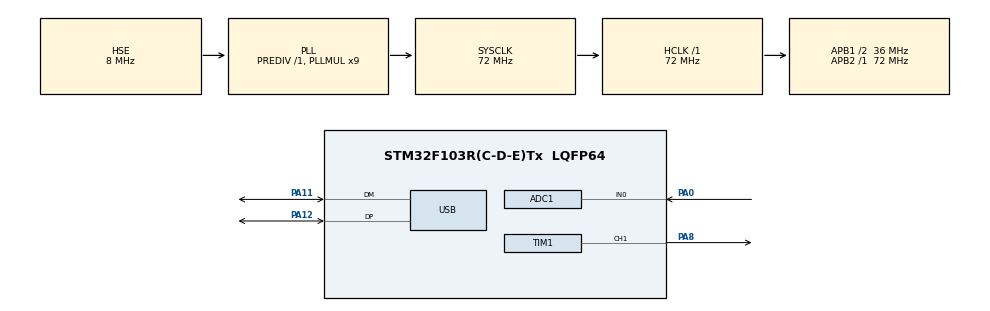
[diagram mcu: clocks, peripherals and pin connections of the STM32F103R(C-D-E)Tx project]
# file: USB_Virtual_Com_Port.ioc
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ADC1.Channel-0\#ChannelRegularConversion=ADC_CHANNEL_0
ADC1.ExternalTrigConv=ADC_EXTERNALTRIGCONV_T3_TRGO
ADC1.InjNumberOfConversion=0
ADC1.NbrOfConversion=1
ADC1.NbrOfConversionFlag=1
ADC1.Rank-0\#ChannelRegularConversion=1
ADC1.SamplingTime-0\#ChannelRegularConversion=ADC_SAMPLETIME_1CYCLE_5
ADC1.master=1
Dma.ADC1.0.Direction=DMA_PERIPH_TO_MEMORY
Dma.ADC1.0.Instance=DMA1_Channel1
Dma.ADC1.0.MemDataAlignment=DMA_MDATAALIGN_HALFWORD
Dma.ADC1.0.MemInc=DMA_MINC_ENABLE
Dma.ADC1.0.Mode=DMA_CIRCULAR
Dma.ADC1.0.PeriphDataAlignment=DMA_PDATAALIGN_HALFWORD
Dma.ADC1.0.PeriphInc=DMA_PINC_DISABLE
Dma.ADC1.0.Priority=DMA_PRIORITY_HIGH
Dma.Request0=ADC1
Mcu.Family=STM32F1
Mcu.Name=STM32F103R(C-D-E)Tx
Mcu.Package=LQFP64
NVIC.DMA1_Channel1_IRQn=true\:0\:0\:false\:false\:true\:false\:true
NVIC.PriorityGroup=NVIC_PRIORITYGROUP_4
NVIC.USB_LP_CAN1_RX0_IRQn=true\:0\:0\:false\:false\:true\:false\:true
PA0-WKUP.Signal=ADCx_IN0
PA11.Mode=Device
PA11.Signal=USB_DM
PA12.Mode=Device
PA12.Signal=USB_DP
PA13.Mode=Serial_Wire
PA13.Signal=SYS_JTMS-SWDIO
PA14.Mode=Serial_Wire
PA14.Signal=SYS_JTCK-SWCLK
PA8.Signal=S_TIM1_CH1
PD0-OSC_IN.Mode=HSE-External-Oscillator
PD0-OSC_IN.Signal=RCC_OSC_IN
PD1-OSC_OUT.Mode=HSE-External-Oscillator
PD1-OSC_OUT.Signal=RCC_OSC_OUT
ProjectManager.HeapSize=0x200
ProjectManager.StackSize=0x400
ProjectManager.TargetToolchain=MDK-ARM V5
RCC.ADCPresc=RCC_ADCPCLK2_DIV6
RCC.AHBFreq_Value=72000000
RCC.APB1CLKDivider=RCC_HCLK_DIV2
RCC.APB1Freq_Value=36000000
RCC.APB1TimFreq_Value=72000000
RCC.APB2Freq_Value=72000000
RCC.APB2TimFreq_Value=72000000
RCC.HCLKFreq_Value=72000000
RCC.PLLMUL=RCC_PLL_MUL9
RCC.PLLSourceVirtual=RCC_PLLSOURCE_HSE
RCC.SYSCLKFreq_VALUE=72000000
RCC.SYSCLKSource=RCC_SYSCLKSOURCE_PLLCLK
RCC.USBFreq_Value=48000000
RCC.USBPrescaler=RCC_USBCLKSOURCE_PLL_DIV1_5
SH.ADCx_IN0.0=ADC1_IN0,IN0
SH.S_TIM1_CH1.0=TIM1_CH1,PWM Generation1 CH1
TIM1.AutomaticOutput=TIM_AUTOMATICOUTPUT_ENABLE
TIM1.Channel-PWM\ Generation1\ CH1=TIM_CHANNEL_1
TIM1.OCPolarity_1=TIM_OCPOLARITY_LOW
TIM1.Period=5000
TIM1.Prescaler=72
TIM1.Pulse-PWM\ Generation1\ CH1=2500
TIM3.Period=1000
TIM3.Prescaler=72
TIM3.TIM_MasterOutputTrigger=TIM_TRGO_UPDATE
USB_DEVICE.APP_RX_DATA_SIZE=50
USB_DEVICE.APP_TX_DATA_SIZE=50
USB_DEVICE.CLASS_NAME_FS=CDC
USB_DEVICE.VirtualMode=Cdc
USB_DEVICE.VirtualModeFS=Cdc_FS
VP_TIM3_VS_ClockSourceINT.Mode=Internal
VP_USB_DEVICE_VS_USB_DEVICE_CDC_FS.Mode=CDC_FS
board=custom

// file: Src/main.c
/* USER CODE BEGIN Header */
/**
  ******************************************************************************
  * @file           : main.c
  * @brief          : Main program body
  ******************************************************************************
  * @attention
  *
  * <h2><center>&copy; Copyright (c) 2020 STMicroelectronics.
  * All rights reserved.</center></h2>
  *
  * This software component is licensed by ST under Ultimate Liberty license
  * SLA0044, the "License"; You may not use this file except in compliance with
  * the License. You may obtain a copy of the License at:
  *                             www.st.com/SLA0044
  *
  ******************************************************************************
  */
/* USER CODE END Header */

#include "main.h"
#include "usb_device.h"

/* USER CODE BEGIN Includes */
uint8_t CDC_Transmit_FS(uint8_t* Buf, uint16_t Len);
/* USER CODE END Includes */

/* USER CODE BEGIN PD */
#define ADC_CALC	3.3/4096
/* USER CODE END PD */

ADC_HandleTypeDef hadc1;
DMA_HandleTypeDef hdma_adc1;

TIM_HandleTypeDef htim1;
TIM_HandleTypeDef htim3;

/* USER CODE BEGIN PV */
uint32_t ADCValue;
char string[]="3.30 Volt \r\n";
/* USER CODE END PV */

void SystemClock_Config(void);
static void MX_GPIO_Init(void);
static void MX_DMA_Init(void);
static void MX_ADC1_Init(void);
static void MX_TIM3_Init(void);
static void MX_TIM1_Init(void);

/* USER CODE BEGIN 0 */
#define APP_RX_DATA_SIZE  50
extern uint8_t UserRxBufferFS[APP_RX_DATA_SIZE];;
/* USER CODE END 0 */

int main(void)
{

  /* MCU Configuration--------------------------------------------------------*/

  /* Reset of all peripherals, Initializes the Flash interface and the Systick. */
  HAL_Init();

  /* Configure the system clock */
  SystemClock_Config();

  /* Initialize all configured peripherals */
  MX_GPIO_Init();
  MX_DMA_Init();
  MX_ADC1_Init();
  MX_TIM3_Init();
  MX_USB_DEVICE_Init();
  MX_TIM1_Init();
  /* USER CODE BEGIN 2 */
	HAL_ADC_Start_DMA(&hadc1,&ADCValue,1);
	HAL_TIM_Base_Start(&htim3);
	HAL_TIM_PWM_Start(&htim1,TIM_CHANNEL_1);
  /* USER CODE END 2 */

  /* Infinite loop */
  while (1)
  {

    /* USER CODE BEGIN 3 */
		sprintf(string,"%.2f",(ADCValue*ADC_CALC));
		CDC_Transmit_FS((uint8_t *)string,sizeof(string));
		HAL_Delay(1000);
		TIM1->CCR1 = UserRxBufferFS[1]<<8 | UserRxBufferFS[0];
  }
  /* USER CODE END 3 */
}

void SystemClock_Config(void)
{
  RCC_OscInitTypeDef RCC_OscInitStruct = {0};
  RCC_ClkInitTypeDef RCC_ClkInitStruct = {0};
  RCC_PeriphCLKInitTypeDef PeriphClkInit = {0};

  /** Initializes the CPU, AHB and APB busses clocks
  */
  RCC_OscInitStruct.OscillatorType = RCC_OSCILLATORTYPE_HSE;
  RCC_OscInitStruct.HSEState = RCC_HSE_ON;
  RCC_OscInitStruct.HSEPredivValue = RCC_HSE_PREDIV_DIV1;
  RCC_OscInitStruct.HSIState = RCC_HSI_ON;
  RCC_OscInitStruct.PLL.PLLState = RCC_PLL_ON;
  RCC_OscInitStruct.PLL.PLLSource = RCC_PLLSOURCE_HSE;
  RCC_OscInitStruct.PLL.PLLMUL = RCC_PLL_MUL9;
  if (HAL_RCC_OscConfig(&RCC_OscInitStruct) != HAL_OK)
  {
    Error_Handler();
  }
  /** Initializes the CPU, AHB and APB busses clocks
  */
  RCC_ClkInitStruct.ClockType = RCC_CLOCKTYPE_HCLK|RCC_CLOCKTYPE_SYSCLK
                              |RCC_CLOCKTYPE_PCLK1|RCC_CLOCKTYPE_PCLK2;
  RCC_ClkInitStruct.SYSCLKSource = RCC_SYSCLKSOURCE_PLLCLK;
  RCC_ClkInitStruct.AHBCLKDivider = RCC_SYSCLK_DIV1;
  RCC_ClkInitStruct.APB1CLKDivider = RCC_HCLK_DIV2;
  RCC_ClkInitStruct.APB2CLKDivider = RCC_HCLK_DIV1;

  if (HAL_RCC_ClockConfig(&RCC_ClkInitStruct, FLASH_LATENCY_2) != HAL_OK)
  {
    Error_Handler();
  }
  PeriphClkInit.PeriphClockSelection = RCC_PERIPHCLK_ADC|RCC_PERIPHCLK_USB;
  PeriphClkInit.AdcClockSelection = RCC_ADCPCLK2_DIV6;
  PeriphClkInit.UsbClockSelection = RCC_USBCLKSOURCE_PLL_DIV1_5;
  if (HAL_RCCEx_PeriphCLKConfig(&PeriphClkInit) != HAL_OK)
  {
    Error_Handler();
  }
}

static void MX_ADC1_Init(void)
{

  ADC_ChannelConfTypeDef sConfig = {0};

  /** Common config
  */
  hadc1.Instance = ADC1;
  hadc1.Init.ScanConvMode = ADC_SCAN_DISABLE;
  hadc1.Init.ContinuousConvMode = DISABLE;
  hadc1.Init.DiscontinuousConvMode = DISABLE;
  hadc1.Init.ExternalTrigConv = ADC_EXTERNALTRIGCONV_T3_TRGO;
  hadc1.Init.DataAlign = ADC_DATAALIGN_RIGHT;
  hadc1.Init.NbrOfConversion = 1;
  if (HAL_ADC_Init(&hadc1) != HAL_OK)
  {
    Error_Handler();
  }
  /** Configure Regular Channel
  */
  sConfig.Channel = ADC_CHANNEL_0;
  sConfig.Rank = ADC_REGULAR_RANK_1;
  sConfig.SamplingTime = ADC_SAMPLETIME_1CYCLE_5;
  if (HAL_ADC_ConfigChannel(&hadc1, &sConfig) != HAL_OK)
  {
    Error_Handler();
  }

}

static void MX_TIM1_Init(void)
{

  TIM_MasterConfigTypeDef sMasterConfig = {0};
  TIM_OC_InitTypeDef sConfigOC = {0};
  TIM_BreakDeadTimeConfigTypeDef sBreakDeadTimeConfig = {0};

  htim1.Instance = TIM1;
  htim1.Init.Prescaler = 72;
  htim1.Init.CounterMode = TIM_COUNTERMODE_UP;
  htim1.Init.Period = 5000;
  htim1.Init.ClockDivision = TIM_CLOCKDIVISION_DIV1;
  htim1.Init.RepetitionCounter = 0;
  htim1.Init.AutoReloadPreload = TIM_AUTORELOAD_PRELOAD_DISABLE;
  if (HAL_TIM_PWM_Init(&htim1) != HAL_OK)
  {
    Error_Handler();
  }
  sMasterConfig.MasterOutputTrigger = TIM_TRGO_RESET;
  sMasterConfig.MasterSlaveMode = TIM_MASTERSLAVEMODE_DISABLE;
  if (HAL_TIMEx_MasterConfigSynchronization(&htim1, &sMasterConfig) != HAL_OK)
  {
    Error_Handler();
  }
  sConfigOC.OCMode = TIM_OCMODE_PWM1;
  sConfigOC.Pulse = 2500;
  sConfigOC.OCPolarity = TIM_OCPOLARITY_LOW;
  sConfigOC.OCNPolarity = TIM_OCNPOLARITY_HIGH;
  sConfigOC.OCFastMode = TIM_OCFAST_DISABLE;
  sConfigOC.OCIdleState = TIM_OCIDLESTATE_RESET;
  sConfigOC.OCNIdleState = TIM_OCNIDLESTATE_RESET;
  if (HAL_TIM_PWM_ConfigChannel(&htim1, &sConfigOC, TIM_CHANNEL_1) != HAL_OK)
  {
    Error_Handler();
  }
  sBreakDeadTimeConfig.OffStateRunMode = TIM_OSSR_DISABLE;
  sBreakDeadTimeConfig.OffStateIDLEMode = TIM_OSSI_DISABLE;
  sBreakDeadTimeConfig.LockLevel = TIM_LOCKLEVEL_OFF;
  sBreakDeadTimeConfig.DeadTime = 0;
  sBreakDeadTimeConfig.BreakState = TIM_BREAK_DISABLE;
  sBreakDeadTimeConfig.BreakPolarity = TIM_BREAKPOLARITY_HIGH;
  sBreakDeadTimeConfig.AutomaticOutput = TIM_AUTOMATICOUTPUT_ENABLE;
  if (HAL_TIMEx_ConfigBreakDeadTime(&htim1, &sBreakDeadTimeConfig) != HAL_OK)
  {
    Error_Handler();
  }
  HAL_TIM_MspPostInit(&htim1);

}

static void MX_TIM3_Init(void)
{

  TIM_ClockConfigTypeDef sClockSourceConfig = {0};
  TIM_MasterConfigTypeDef sMasterConfig = {0};

  htim3.Instance = TIM3;
  htim3.Init.Prescaler = 72;
  htim3.Init.CounterMode = TIM_COUNTERMODE_UP;
  htim3.Init.Period = 1000;
  htim3.Init.ClockDivision = TIM_CLOCKDIVISION_DIV1;
  htim3.Init.AutoReloadPreload = TIM_AUTORELOAD_PRELOAD_DISABLE;
  if (HAL_TIM_Base_Init(&htim3) != HAL_OK)
  {
    Error_Handler();
  }
  sClockSourceConfig.ClockSource = TIM_CLOCKSOURCE_INTERNAL;
  if (HAL_TIM_ConfigClockSource(&htim3, &sClockSourceConfig) != HAL_OK)
  {
    Error_Handler();
  }
  sMasterConfig.MasterOutputTrigger = TIM_TRGO_UPDATE;
  sMasterConfig.MasterSlaveMode = TIM_MASTERSLAVEMODE_DISABLE;
  if (HAL_TIMEx_MasterConfigSynchronization(&htim3, &sMasterConfig) != HAL_OK)
  {
    Error_Handler();
  }

}

static void MX_DMA_Init(void)
{
  /* DMA controller clock enable */
  __HAL_RCC_DMA1_CLK_ENABLE();

  /* DMA interrupt init */
  /* DMA1_Channel1_IRQn interrupt configuration */
  HAL_NVIC_SetPriority(DMA1_Channel1_IRQn, 0, 0);
  HAL_NVIC_EnableIRQ(DMA1_Channel1_IRQn);

}

static void MX_GPIO_Init(void)
{
  GPIO_InitTypeDef GPIO_InitStruct = {0};

  /* GPIO Ports Clock Enable */
  __HAL_RCC_GPIOC_CLK_ENABLE();
  __HAL_RCC_GPIOD_CLK_ENABLE();
  __HAL_RCC_GPIOA_CLK_ENABLE();
  __HAL_RCC_GPIOB_CLK_ENABLE();

  /*Configure GPIO pins : PC13 PC14 PC15 PC0
                           PC1 PC2 PC3 PC4
                           PC5 PC6 PC7 PC8
                           PC9 PC10 PC11 PC12 */
  GPIO_InitStruct.Pin = GPIO_PIN_13|GPIO_PIN_14|GPIO_PIN_15|GPIO_PIN_0
                          |GPIO_PIN_1|GPIO_PIN_2|GPIO_PIN_3|GPIO_PIN_4
                          |GPIO_PIN_5|GPIO_PIN_6|GPIO_PIN_7|GPIO_PIN_8
                          |GPIO_PIN_9|GPIO_PIN_10|GPIO_PIN_11|GPIO_PIN_12;
  GPIO_InitStruct.Mode = GPIO_MODE_ANALOG;
  HAL_GPIO_Init(GPIOC, &GPIO_InitStruct);

  /*Configure GPIO pins : PA1 PA2 PA3 PA4
                           PA5 PA6 PA7 PA9
                           PA10 PA15 */
  GPIO_InitStruct.Pin = GPIO_PIN_1|GPIO_PIN_2|GPIO_PIN_3|GPIO_PIN_4
                          |GPIO_PIN_5|GPIO_PIN_6|GPIO_PIN_7|GPIO_PIN_9
                          |GPIO_PIN_10|GPIO_PIN_15;
  GPIO_InitStruct.Mode = GPIO_MODE_ANALOG;
  HAL_GPIO_Init(GPIOA, &GPIO_InitStruct);

  /*Configure GPIO pins : PB0 PB1 PB2 PB10
                           PB11 PB12 PB13 PB14
                           PB15 PB3 PB4 PB5
                           PB6 PB7 PB8 PB9 */
  GPIO_InitStruct.Pin = GPIO_PIN_0|GPIO_PIN_1|GPIO_PIN_2|GPIO_PIN_10
                          |GPIO_PIN_11|GPIO_PIN_12|GPIO_PIN_13|GPIO_PIN_14
                          |GPIO_PIN_15|GPIO_PIN_3|GPIO_PIN_4|GPIO_PIN_5
                          |GPIO_PIN_6|GPIO_PIN_7|GPIO_PIN_8|GPIO_PIN_9;
  GPIO_InitStruct.Mode = GPIO_MODE_ANALOG;
  HAL_GPIO_Init(GPIOB, &GPIO_InitStruct);

  /*Configure GPIO pin : PD2 */
  GPIO_InitStruct.Pin = GPIO_PIN_2;
  GPIO_InitStruct.Mode = GPIO_MODE_ANALOG;
  HAL_GPIO_Init(GPIOD, &GPIO_InitStruct);

}

void Error_Handler(void)
{
}

/************************ (C) COPYRIGHT STMicroelectronics *****END OF FILE****/
